VERSION ""

NS_ :

BS_:

BU_: XXX

BO_ 258 STEERING: 8 XXX
 SG_ STEER_ANGLE : 4|13@0+ (0.3187251,-1307.888) [-360|360] "deg" XXX

BO_ 514 SPEED: 8 XXX
 SG_ SPEED : 7|12@0+ (0.07,0) [0|65535] "m/s" XXX

BO_ 653 BRAKE_MODULE: 8 XXX
 SG_ BRAKE_PRESSURE : 15|8@0+ (1,0) [0|255] "" XXX
 SG_ BRAKE_PRESSED : 4|1@0+ (1,0) [0|4] "" XXX

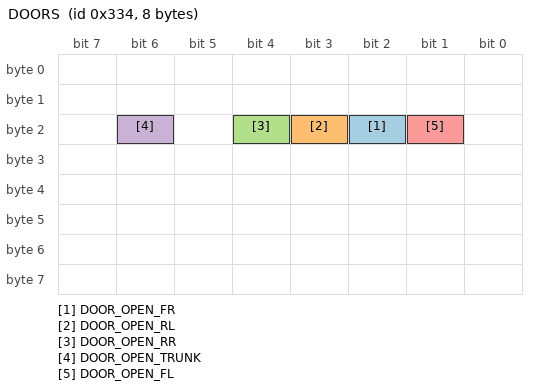
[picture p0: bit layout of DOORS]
BO_ 820 DOORS: 8 XXX
 SG_ DOOR_OPEN_FR : 18|1@0+ (1,0) [0|1] "" XXX
 SG_ DOOR_OPEN_RL : 19|1@0+ (1,0) [0|1] "" XXX
 SG_ DOOR_OPEN_RR : 20|1@0+ (1,0) [0|1] "" XXX
 SG_ DOOR_OPEN_TRUNK : 22|1@0+ (1,0) [0|1] "" XXX
 SG_ DOOR_OPEN_FL : 17|1@0+ (1,0) [0|1] "" XXX

CM_ SG_ 258 STEER_ANGLE "positive is left (counter-clockwise)";
CM_ SG_ 514 SPEED "TODO find upper limit";
